# STM32F102 register map
File version: 1.1
CPU: CM3 r1p1, little endian, no MPU, no FPU, 4 interrupt priority bits
Registers are 32-bit, read-write, reset 0x0 unless marked. A register's access mark holds for its fields unless they carry their own. Offsets are from the block's base; [hi:lo] are bit positions; lines under a group give offsets from that group; {n}, {i} and the like mark numbered series; 'fields as' and 'values as' point back to an identical list.

## FSMC — Flexible static memory controller
Base 0xA0000000
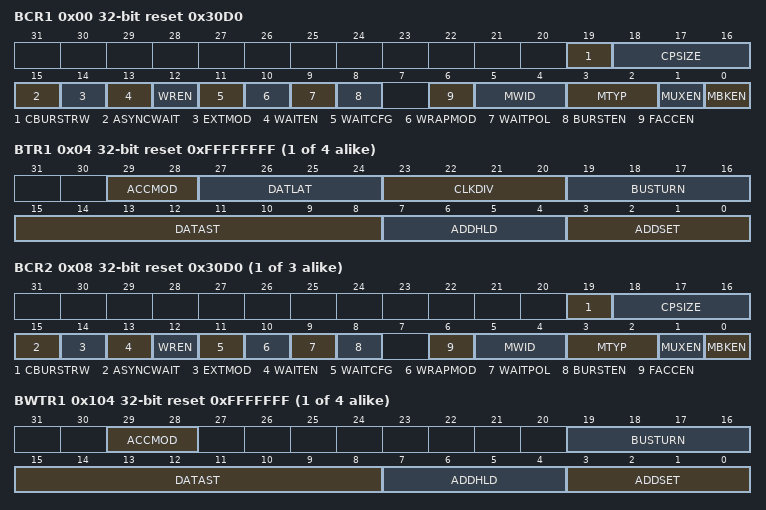
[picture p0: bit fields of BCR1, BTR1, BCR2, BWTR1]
0x00 BCR1 reset 0x30D0 — SRAM/NOR-Flash chip-select control register 1
  [19] CBURSTRW
    0=Disabled (Write operations are always performed in asynchronous mode); 1=Enabled (Write operations are performed in synchronous mode)
  [18:16] CPSIZE — CRAM page size
    0=No burst split when crossing page boundary; 1=Bytes128 (128 bytes CRAM page size); 2=Bytes256 (256 bytes CRAM page size); 3=Bytes512 (512 bytes CRAM page size); 4=Bytes1024 (1024 bytes CRAM page size)
  [15] ASYNCWAIT
    0=Disabled (Wait signal not used in asynchronous mode); 1=Enabled (Wait signal used even in asynchronous mode)
  [14] EXTMOD
    0=Disabled (Values inside the FMC_BWTR are not taken into account); 1=Enabled (Values inside the FMC_BWTR are taken into account)
  [13] WAITEN
    0=Disabled (Values inside the FMC_BWTR are taken into account); 1=Enabled (NWAIT signal enabled)
  [12] WREN
    0=Disabled (Write operations disabled for the bank by the FMC); 1=Enabled (Write operations enabled for the bank by the FMC)
  [11] WAITCFG
    0=BeforeWaitState (NWAIT signal is active one data cycle before wait state); 1=DuringWaitState (NWAIT signal is active during wait state)
  [10] WRAPMOD
    0=Disabled (Direct wrapped burst is not enabled); 1=Enabled (Direct wrapped burst is enabled)
  [9] WAITPOL
    0=ActiveLow (NWAIT active low); 1=ActiveHigh (NWAIT active high)
  [8] BURSTEN
    0=Disabled (Burst mode disabled); 1=Enabled (Burst mode enabled)
  [6] FACCEN
    0=Disabled (Corresponding NOR Flash memory access is disabled); 1=Enabled (Corresponding NOR Flash memory access is enabled)
  [5:4] MWID
    0=Bits8 (Memory data bus width 8 bits); 1=Bits16 (Memory data bus width 16 bits); 2=Bits32 (Memory data bus width 32 bits)
  [3:2] MTYP
    0=SRAM (SRAM memory type); 1=PSRAM (PSRAM (CRAM) memory type); 2=Flash (NOR Flash/OneNAND Flash)
  [1] MUXEN
    0=Disabled (Address/Data non-multiplexed); 1=Enabled (Address/Data multiplexed on databus)
  [0] MBKEN
    0=Disabled (Corresponding memory bank is disabled); 1=Enabled (Corresponding memory bank is enabled)
0x04 BTR{i} (i=1..4; step 0x8) reset 0xFFFFFFFF — SRAM/NOR-Flash chip-select timing register {i}
  [29:28] ACCMOD
    0=A (Access mode A); 1=B (Access mode B); 2=C (Access mode C); 3=D (Access mode D)
  [27:24] DATLAT
  [23:20] CLKDIV range 1..15
  [19:16] BUSTURN
  [15:8] DATAST range 1..255
  [7:4] ADDHLD range 1..15
  [3:0] ADDSET
0x08 BCR{i} (i=2..4; step 0x8) reset 0x30D0 — SRAM/NOR-Flash chip-select control register {i}
  fields as BCR1
{0xFC+8i} BWTR{i} (i=1..4) reset 0xFFFFFFF — SRAM/NOR-Flash write timing registers {i}
  [29:28] ACCMOD
    values as BTR{i}.ACCMOD
  [19:16] BUSTURN — Bus turnaround phase duration
  [15:8] DATAST range 1..255
  [7:4] ADDHLD range 1..15
  [3:0] ADDSET

## OTG_FS_HOST — USB on the go full speed
Base 0x50000400
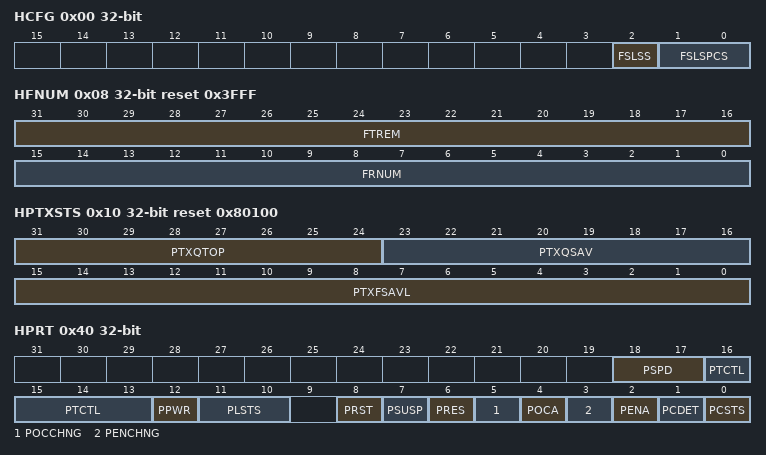
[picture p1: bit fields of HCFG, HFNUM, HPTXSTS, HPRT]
0x00 HCFG — OTG_FS host configuration register (OTG_FS_HCFG)
  [2] FSLSS — FS- and LS-only support
  [1:0] FSLSPCS — FS/LS PHY clock select
0x04 HFIR reset 0xEA60 — OTG_FS Host frame interval register
  [15:0] FRIVL — Frame interval
0x08 HFNUM ro reset 0x3FFF — OTG_FS host frame number/frame time remaining register (OTG_FS_HFNUM)
  [31:16] FTREM — Frame time remaining
  [15:0] FRNUM — Frame number
0x10 HPTXSTS access per field reset 0x80100 — OTG_FS_Host periodic transmit FIFO/queue status register (OTG_FS_HPTXSTS)
  [31:24] PTXQTOP ro — Top of the periodic transmit request queue
  [23:16] PTXQSAV ro — Periodic transmit request queue space available
  [15:0] PTXFSAVL rw — Periodic transmit data FIFO space available
0x14 HAINT ro — OTG_FS Host all channels interrupt register
  [15:0] HAINT — Channel interrupts
0x18 HAINTMSK — OTG_FS host all channels interrupt mask register
  [15:0] HAINTM — Channel interrupt mask
0x40 HPRT access per field — OTG_FS host port control and status register (OTG_FS_HPRT)
  [18:17] PSPD ro — Port speed
  [16:13] PTCTL rw — Port test control
  [12] PPWR rw — Port power
  [11:10] PLSTS ro — Port line status
  [8] PRST rw — Port reset
  [7] PSUSP rw — Port suspend
  [6] PRES rw — Port resume
  [5] POCCHNG rw — Port overcurrent change
  [4] POCA ro — Port overcurrent active
  [3] PENCHNG rw — Port enable/disable change
  [2] PENA rw — Port enable
  [1] PCDET rw — Port connect detected
  [0] PCSTS ro — Port connect status
{0x100+0x20*i} HC{i} (i=0..7) group — Host channel
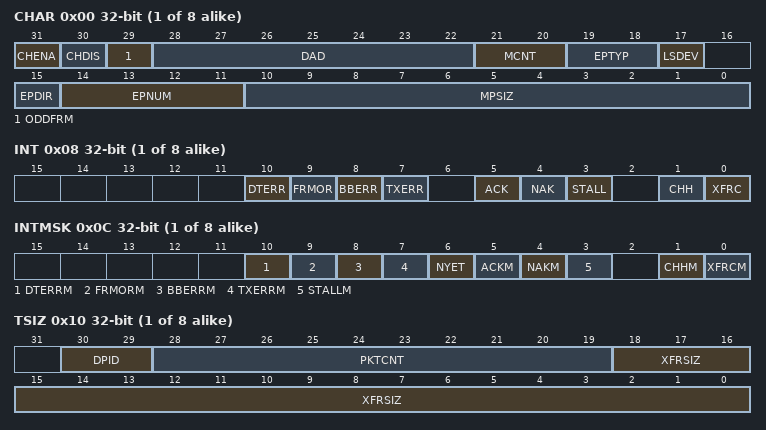
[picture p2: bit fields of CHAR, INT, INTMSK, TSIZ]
  0x00 CHAR — OTG_FS host channel-0 characteristics register (OTG_FS_HCCHAR0)
    [31] CHENA — Channel enable
    [30] CHDIS — Channel disable
    [29] ODDFRM — Odd frame
    [28:22] DAD — Device address
    [21:20] MCNT — Multicount
    [19:18] EPTYP — Endpoint type
    [17] LSDEV — Low-speed device
    [15] EPDIR — Endpoint direction
    [14:11] EPNUM — Endpoint number
    [10:0] MPSIZ — Maximum packet size
  0x08 INT — OTG_FS host channel-0 interrupt register (OTG_FS_HCINT0)
    [10] DTERR — Data toggle error
    [9] FRMOR — Frame overrun
    [8] BBERR — Babble error
    [7] TXERR — Transaction error
    [5] ACK — ACK response received/transmitted interrupt
    [4] NAK — NAK response received interrupt
    [3] STALL — STALL response received interrupt
    [1] CHH — Channel halted
    [0] XFRC — Transfer completed
  0x0C INTMSK — OTG_FS host channel-0 mask register (OTG_FS_HCINTMSK0)
    [10] DTERRM — Data toggle error mask
    [9] FRMORM — Frame overrun mask
    [8] BBERRM — Babble error mask
    [7] TXERRM — Transaction error mask
    [6] NYET — response received interrupt mask
    [5] ACKM — ACK response received/transmitted interrupt mask
    [4] NAKM — NAK response received interrupt mask
    [3] STALLM — STALL response received interrupt mask
    [1] CHHM — Channel halted mask
    [0] XFRCM — Transfer completed mask
  0x10 TSIZ — OTG_FS host channel-0 transfer size register
    [30:29] DPID — Data PID
    [28:19] PKTCNT — Packet count
    [18:0] XFRSIZ — Transfer size
